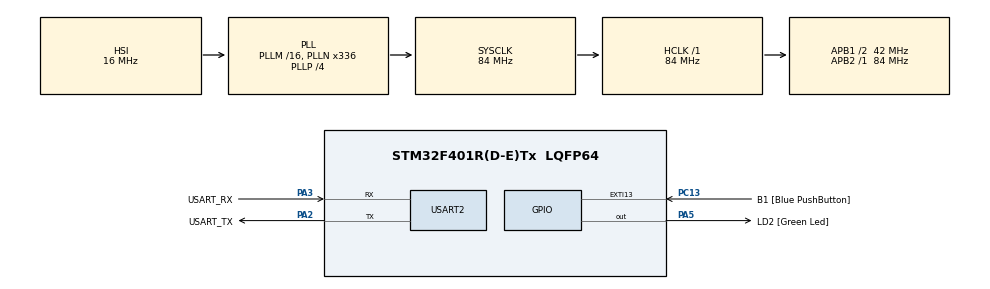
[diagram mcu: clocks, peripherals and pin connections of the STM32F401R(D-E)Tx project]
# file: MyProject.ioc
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Dma.Request0=USART2_TX
Dma.Request1=USART2_RX
Dma.USART2_RX.1.Direction=DMA_PERIPH_TO_MEMORY
Dma.USART2_RX.1.FIFOMode=DMA_FIFOMODE_DISABLE
Dma.USART2_RX.1.Instance=DMA1_Stream5
Dma.USART2_RX.1.MemDataAlignment=DMA_MDATAALIGN_BYTE
Dma.USART2_RX.1.MemInc=DMA_MINC_ENABLE
Dma.USART2_RX.1.Mode=DMA_NORMAL
Dma.USART2_RX.1.PeriphDataAlignment=DMA_PDATAALIGN_BYTE
Dma.USART2_RX.1.PeriphInc=DMA_PINC_DISABLE
Dma.USART2_RX.1.Priority=DMA_PRIORITY_LOW
Dma.USART2_TX.0.Direction=DMA_MEMORY_TO_PERIPH
Dma.USART2_TX.0.FIFOMode=DMA_FIFOMODE_DISABLE
Dma.USART2_TX.0.Instance=DMA1_Stream6
Dma.USART2_TX.0.MemDataAlignment=DMA_MDATAALIGN_BYTE
Dma.USART2_TX.0.MemInc=DMA_MINC_ENABLE
Dma.USART2_TX.0.Mode=DMA_NORMAL
Dma.USART2_TX.0.PeriphDataAlignment=DMA_PDATAALIGN_BYTE
Dma.USART2_TX.0.PeriphInc=DMA_PINC_DISABLE
Dma.USART2_TX.0.Priority=DMA_PRIORITY_LOW
Mcu.Family=STM32F4
Mcu.Name=STM32F401R(D-E)Tx
Mcu.Package=LQFP64
NVIC.DMA1_Stream5_IRQn=true\:0\:0\:false\:false\:true\:false
NVIC.DMA1_Stream6_IRQn=true\:0\:0\:false\:false\:true\:false
NVIC.EXTI15_10_IRQn=true\:0\:0\:false\:false\:true\:true
NVIC.PriorityGroup=NVIC_PRIORITYGROUP_0
NVIC.USART2_IRQn=true\:0\:0\:false\:false\:true\:true
PA13.GPIO_Label=TMS
PA13.Signal=SYS_JTMS-SWDIO
PA14.GPIO_Label=TCK
PA14.Signal=SYS_JTCK-SWCLK
PA2.GPIO_Label=USART_TX
PA2.GPIO_Mode=GPIO_MODE_AF_PP
PA2.GPIO_PuPd=GPIO_NOPULL
PA2.GPIO_Speed=GPIO_SPEED_FREQ_LOW
PA2.Mode=Asynchronous
PA2.Signal=USART2_TX
PA3.GPIO_Label=USART_RX
PA3.GPIO_Mode=GPIO_MODE_AF_PP
PA3.GPIO_PuPd=GPIO_NOPULL
PA3.GPIO_Speed=GPIO_SPEED_FREQ_LOW
PA3.Mode=Asynchronous
PA3.Signal=USART2_RX
PA5.GPIO_Label=LD2 [Green Led]
PA5.GPIO_Mode=GPIO_MODE_OUTPUT_PP
PA5.GPIO_PuPd=GPIO_NOPULL
PA5.GPIO_Speed=GPIO_SPEED_FREQ_LOW
PA5.Signal=GPIO_Output
PB3.GPIO_Label=SWO
PB3.Signal=SYS_JTDO-SWO
PC13-ANTI_TAMP.GPIO_Label=B1 [Blue PushButton]
PC13-ANTI_TAMP.GPIO_ModeDefaultEXTI=GPIO_MODE_IT_FALLING
PC13-ANTI_TAMP.GPIO_PuPd=GPIO_NOPULL
PC13-ANTI_TAMP.Signal=GPXTI13
PC14-OSC32_IN.Signal=RCC_OSC32_IN
PC15-OSC32_OUT.Signal=RCC_OSC32_OUT
PH0\ -\ OSC_IN.Signal=RCC_OSC_IN
PH1\ -\ OSC_OUT.Signal=RCC_OSC_OUT
ProjectManager.HeapSize=0x200
ProjectManager.StackSize=0x400
ProjectManager.TargetToolchain=MDK-ARM V5
RCC.AHBFreq_Value=84000000
RCC.APB1CLKDivider=RCC_HCLK_DIV2
RCC.APB1Freq_Value=42000000
RCC.APB1TimFreq_Value=84000000
RCC.APB2Freq_Value=84000000
RCC.APB2TimFreq_Value=84000000
RCC.CortexFreq_Value=84000000
RCC.HCLKFreq_Value=84000000
RCC.HSE_VALUE=8000000
RCC.HSI_VALUE=16000000
RCC.LSE_VALUE=32768
RCC.PLLN=336
RCC.PLLP=RCC_PLLP_DIV4
RCC.PLLQ=7
RCC.SYSCLKFreq_VALUE=84000000
RCC.SYSCLKSource=RCC_SYSCLKSOURCE_PLLCLK
RCC.VCOOutputFreq_Value=336000000
USART2.VirtualMode=VM_ASYNC
VP_TIM2_VS_ClockSourceINT.Mode=Internal
VP_TIM2_VS_ClockSourceITR.Mode=TriggerSource_ITR0
VP_TIM2_VS_ControllerModeTrigger.Mode=Trigger Mode
board=NUCLEO-F401RE

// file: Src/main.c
#include "main.h"
#include "stm32f4xx_hal.h"

TIM_HandleTypeDef htim2;

UART_HandleTypeDef huart2;
DMA_HandleTypeDef hdma_usart2_tx;
DMA_HandleTypeDef hdma_usart2_rx;

/* USER CODE BEGIN PV */
/* Private variables ---------------------------------------------------------*/

/* USER CODE END PV */

void SystemClock_Config(void);
static void MX_GPIO_Init(void);
static void MX_DMA_Init(void);
static void MX_TIM2_Init(void);
static void MX_USART2_UART_Init(void);

/* USER CODE BEGIN PFP */
/* Private function prototypes -----------------------------------------------*/

/* USER CODE END PFP */

int main(void)
{

  /* USER CODE BEGIN 1 */

	HAL_GPIO_WritePin(GPIOA, GPIO_PIN_5, GPIO_PIN_SET);
  HAL_Delay(1000);
	HAL_GPIO_WritePin(GPIOA, GPIO_PIN_5, GPIO_PIN_RESET);
	HAL_Delay(1000);

  /* USER CODE END 1 */

  /* MCU Configuration----------------------------------------------------------*/

  /* Reset of all peripherals, Initializes the Flash interface and the Systick. */
  HAL_Init();

  /* Configure the system clock */
  SystemClock_Config();

  /* Initialize all configured peripherals */
  MX_GPIO_Init();
  MX_DMA_Init();
  MX_TIM2_Init();
  MX_USART2_UART_Init();

  /* Infinite loop */
  while (1)
  {

  }

}

/** System Clock Configuration
*/
void SystemClock_Config(void)
{

  RCC_OscInitTypeDef RCC_OscInitStruct;
  RCC_ClkInitTypeDef RCC_ClkInitStruct;

    /**Configure the main internal regulator output voltage
    */
  __HAL_RCC_PWR_CLK_ENABLE();

  __HAL_PWR_VOLTAGESCALING_CONFIG(PWR_REGULATOR_VOLTAGE_SCALE2);

    /**Initializes the CPU, AHB and APB busses clocks
    */
  RCC_OscInitStruct.OscillatorType = RCC_OSCILLATORTYPE_HSI;
  RCC_OscInitStruct.HSIState = RCC_HSI_ON;
  RCC_OscInitStruct.HSICalibrationValue = 16;
  RCC_OscInitStruct.PLL.PLLState = RCC_PLL_ON;
  RCC_OscInitStruct.PLL.PLLSource = RCC_PLLSOURCE_HSI;
  RCC_OscInitStruct.PLL.PLLM = 16;
  RCC_OscInitStruct.PLL.PLLN = 336;
  RCC_OscInitStruct.PLL.PLLP = RCC_PLLP_DIV4;
  RCC_OscInitStruct.PLL.PLLQ = 7;
  if (HAL_RCC_OscConfig(&RCC_OscInitStruct) != HAL_OK)
  {
    _Error_Handler(__FILE__, __LINE__);
  }

    /**Initializes the CPU, AHB and APB busses clocks
    */
  RCC_ClkInitStruct.ClockType = RCC_CLOCKTYPE_HCLK|RCC_CLOCKTYPE_SYSCLK
                              |RCC_CLOCKTYPE_PCLK1|RCC_CLOCKTYPE_PCLK2;
  RCC_ClkInitStruct.SYSCLKSource = RCC_SYSCLKSOURCE_PLLCLK;
  RCC_ClkInitStruct.AHBCLKDivider = RCC_SYSCLK_DIV1;
  RCC_ClkInitStruct.APB1CLKDivider = RCC_HCLK_DIV2;
  RCC_ClkInitStruct.APB2CLKDivider = RCC_HCLK_DIV1;

  if (HAL_RCC_ClockConfig(&RCC_ClkInitStruct, FLASH_LATENCY_2) != HAL_OK)
  {
    _Error_Handler(__FILE__, __LINE__);
  }

    /**Configure the Systick interrupt time
    */
  HAL_SYSTICK_Config(HAL_RCC_GetHCLKFreq()/1000);

    /**Configure the Systick
    */
  HAL_SYSTICK_CLKSourceConfig(SYSTICK_CLKSOURCE_HCLK);

  /* SysTick_IRQn interrupt configuration */
  HAL_NVIC_SetPriority(SysTick_IRQn, 0, 0);
}

/* TIM2 init function */
static void MX_TIM2_Init(void)
{

  TIM_ClockConfigTypeDef sClockSourceConfig;
  TIM_SlaveConfigTypeDef sSlaveConfig;
  TIM_MasterConfigTypeDef sMasterConfig;

  htim2.Instance = TIM2;
  htim2.Init.Prescaler = 0;
  htim2.Init.CounterMode = TIM_COUNTERMODE_UP;
  htim2.Init.Period = 0;
  htim2.Init.ClockDivision = TIM_CLOCKDIVISION_DIV1;
  if (HAL_TIM_Base_Init(&htim2) != HAL_OK)
  {
    _Error_Handler(__FILE__, __LINE__);
  }

  sClockSourceConfig.ClockSource = TIM_CLOCKSOURCE_INTERNAL;
  if (HAL_TIM_ConfigClockSource(&htim2, &sClockSourceConfig) != HAL_OK)
  {
    _Error_Handler(__FILE__, __LINE__);
  }

  sSlaveConfig.SlaveMode = TIM_SLAVEMODE_TRIGGER;
  sSlaveConfig.InputTrigger = TIM_TS_ITR0;
  if (HAL_TIM_SlaveConfigSynchronization(&htim2, &sSlaveConfig) != HAL_OK)
  {
    _Error_Handler(__FILE__, __LINE__);
  }

  sMasterConfig.MasterOutputTrigger = TIM_TRGO_RESET;
  sMasterConfig.MasterSlaveMode = TIM_MASTERSLAVEMODE_DISABLE;
  if (HAL_TIMEx_MasterConfigSynchronization(&htim2, &sMasterConfig) != HAL_OK)
  {
    _Error_Handler(__FILE__, __LINE__);
  }

}

/* USART2 init function */
static void MX_USART2_UART_Init(void)
{

  huart2.Instance = USART2;
  huart2.Init.BaudRate = 115200;
  huart2.Init.WordLength = UART_WORDLENGTH_8B;
  huart2.Init.StopBits = UART_STOPBITS_1;
  huart2.Init.Parity = UART_PARITY_NONE;
  huart2.Init.Mode = UART_MODE_TX_RX;
  huart2.Init.HwFlowCtl = UART_HWCONTROL_NONE;
  huart2.Init.OverSampling = UART_OVERSAMPLING_16;
  if (HAL_UART_Init(&huart2) != HAL_OK)
  {
    _Error_Handler(__FILE__, __LINE__);
  }

}

static void MX_DMA_Init(void)
{
  /* DMA controller clock enable */
  __HAL_RCC_DMA1_CLK_ENABLE();

  /* DMA interrupt init */
  /* DMA1_Stream5_IRQn interrupt configuration */
  HAL_NVIC_SetPriority(DMA1_Stream5_IRQn, 0, 0);
  HAL_NVIC_EnableIRQ(DMA1_Stream5_IRQn);
  /* DMA1_Stream6_IRQn interrupt configuration */
  HAL_NVIC_SetPriority(DMA1_Stream6_IRQn, 0, 0);
  HAL_NVIC_EnableIRQ(DMA1_Stream6_IRQn);

}

/** Configure pins as
        * Analog
        * Input
        * Output
        * EVENT_OUT
        * EXTI
*/
static void MX_GPIO_Init(void)
{

  GPIO_InitTypeDef GPIO_InitStruct;

  /* GPIO Ports Clock Enable */
  __HAL_RCC_GPIOC_CLK_ENABLE();
  __HAL_RCC_GPIOH_CLK_ENABLE();
  __HAL_RCC_GPIOA_CLK_ENABLE();
  __HAL_RCC_GPIOB_CLK_ENABLE();

  /*Configure GPIO pin Output Level */
  HAL_GPIO_WritePin(LD2_GPIO_Port, LD2_Pin, GPIO_PIN_RESET);

  /*Configure GPIO pin : B1_Pin */
  GPIO_InitStruct.Pin = B1_Pin;
  GPIO_InitStruct.Mode = GPIO_MODE_IT_FALLING;
  GPIO_InitStruct.Pull = GPIO_NOPULL;
  HAL_GPIO_Init(B1_GPIO_Port, &GPIO_InitStruct);

  /*Configure GPIO pin : LD2_Pin */
  GPIO_InitStruct.Pin = LD2_Pin;
  GPIO_InitStruct.Mode = GPIO_MODE_OUTPUT_PP;
  GPIO_InitStruct.Pull = GPIO_NOPULL;
  GPIO_InitStruct.Speed = GPIO_SPEED_FREQ_LOW;
  HAL_GPIO_Init(LD2_GPIO_Port, &GPIO_InitStruct);

  /* EXTI interrupt init*/
  HAL_NVIC_SetPriority(EXTI15_10_IRQn, 0, 0);
  HAL_NVIC_EnableIRQ(EXTI15_10_IRQn);

}

void _Error_Handler(char * file, int line)
{
  while(1)
  {
  }
}

/************************ (C) COPYRIGHT STMicroelectronics *****END OF FILE****/
